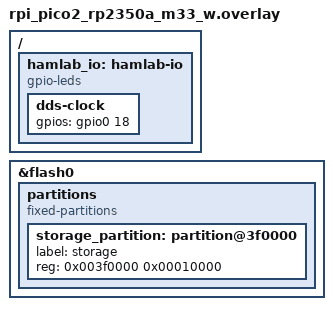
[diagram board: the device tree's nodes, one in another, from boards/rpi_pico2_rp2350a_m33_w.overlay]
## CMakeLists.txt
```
cmake_minimum_required(VERSION 3.20.0)
find_package(Zephyr REQUIRED HINTS $ENV{ZEPHYR_BASE})
project(hamlab)
target_sources(app PRIVATE src/main.c src/network/network.c src/network/tcp_console.c)
```

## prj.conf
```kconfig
CONFIG_GPIO=y
CONFIG_NETWORKING=y
CONFIG_NET_IPV4=y
CONFIG_NET_DHCPV4=y
CONFIG_NET_TCP=y
CONFIG_NET_SOCKETS=y
CONFIG_WIFI=y
CONFIG_NET_MGMT=y
CONFIG_NET_MGMT_EVENT=y
CONFIG_NET_SHELL=y
CONFIG_SHELL=y
CONFIG_SHELL_BACKEND_SERIAL=y
CONFIG_SHELL_BACKEND_TELNET=n
CONFIG_SHELL_BACKEND_DUMMY=y
CONFIG_SHELL_BACKEND_DUMMY_BUF_SIZE=8192
CONFIG_MAIN_STACK_SIZE=4096
CONFIG_SYSTEM_WORKQUEUE_STACK_SIZE=2048
CONFIG_HEAP_MEM_POOL_SIZE=8192
CONFIG_LOG=y
CONFIG_PICOLIBC_IO_FLOAT=y
CONFIG_UDC_DRIVER_LOG_LEVEL_OFF=y
CONFIG_SHELL_STACK_SIZE=5200
CONFIG_NET_TX_STACK_SIZE=2048
CONFIG_NET_RX_STACK_SIZE=2048
CONFIG_NET_PKT_RX_COUNT=16
CONFIG_NET_PKT_TX_COUNT=32
CONFIG_NET_BUF_RX_COUNT=32
CONFIG_NET_BUF_TX_COUNT=64
CONFIG_NET_MAX_CONTEXTS=16
CONFIG_NET_MAX_CONN=16
CONFIG_WIFI_USAGE_MODE_STA=y
CONFIG_NET_L2_WIFI_MGMT=y
CONFIG_NET_L2_WIFI_SHELL=y
CONFIG_NET_CONNECTION_MANAGER=y
CONFIG_NET_MGMT_EVENT_STACK_SIZE=1536
CONFIG_NET_MGMT_EVENT_QUEUE_TIMEOUT=5000
CONFIG_NET_MGMT_EVENT_QUEUE_SIZE=16
CONFIG_WIFI_CREDENTIALS=y
CONFIG_WIFI_CREDENTIALS_BACKEND_SETTINGS=y
CONFIG_SETTINGS=y
CONFIG_FLASH=y
CONFIG_FLASH_MAP=y
CONFIG_NVS=y
CONFIG_SETTINGS_NVS=y
CONFIG_USBD_CDC_ACM_BUF_POOL=y
CONFIG_USBD_CDC_ACM_BUF_POOL_SIZE=4096
```

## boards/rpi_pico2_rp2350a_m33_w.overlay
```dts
/* HamLab uses GPIO directly. See README for the full pin table. */
/ {
    hamlab_io: hamlab-io {
        compatible = "gpio-leds";
        dds-clock { gpios = <&gpio0 18 GPIO_ACTIVE_HIGH>; };
    };
};

/* Identical Settings/NVS storage layout to pico-zephyr-transceiver-control/app.overlay. */
&flash0 {
    partitions {
        compatible = "fixed-partitions";
        #address-cells = <1>;
        #size-cells = <1>;

        storage_partition: partition@3f0000 {
            label = "storage";
            reg = <0x003f0000 0x00010000>;
        };
    };
};
```

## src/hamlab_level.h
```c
#ifndef HAMLAB_LEVEL_H
#define HAMLAB_LEVEL_H
#include <stdint.h>
/* Scope-average reference, 50 ohm sine, 2026-10-01. Offsets include
 * the previous A1 alignment. Endpoints held outside 1..30 MHz. */
static inline double level_offset(int channel,uint32_t hz) {
    const double a[2][3]={{-19.47,-19.39,-18.35},{-19.60,-19.50,-18.46}};
    if(hz<=1000000U)return a[channel][0];
    if(hz>=30000000U)return a[channel][2];
    unsigned i=hz<=7000000U?0:1;
    double lo=i?7000000.0:1000000.0,hi=i?30000000.0:7000000.0;
    return a[channel][i]+(a[channel][i+1]-a[channel][i])*((double)hz-lo)/(hi-lo);
}
#endif
```

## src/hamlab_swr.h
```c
#ifndef HAMLAB_SWR_H
#define HAMLAB_SWR_H
#include <stdint.h>
#include <math.h>
/* Self-built DJ0ABR coupler, closed lid, FY6900; A1 forward, A0 reverse.
 * Open normalization only. Load curve is a quality reference, not vector correction. */
static const struct { uint32_t hz; double open_delta, limit; } swr_cal[] = {
    {1000000U, 0.028000, 26.111000},
    {2000000U, 0.032000, 26.028000},
    {3000000U, 0.054000, 26.091000},
    {4000000U, 0.037000, 26.194000},
    {5000000U, 0.015000, 26.325000},
    {6000000U, 0.039000, 26.449000},
    {7000000U, 0.030000, 26.574000},
    {8000000U, 0.054000, 26.769000},
    {9000000U, 0.027000, 26.909000},
    {10000000U, 0.093000, 27.176000},
    {11000000U, 0.033000, 27.389000},
    {12000000U, 0.004000, 27.570000},
    {13000000U, 0.007000, 27.872000},
    {14000000U, 0.008000, 28.095000},
    {15000000U, 0.009000, 28.377000},
    {16000000U, -0.007000, 28.672000},
    {17000000U, -0.002000, 28.966000},
    {18000000U, 0.011000, 29.306000},
    {19000000U, -0.012000, 29.611000},
    {20000000U, 0.065000, 30.167000},
    {21000000U, -0.024000, 30.178000},
    {22000000U, -0.053000, 30.438000},
    {23000000U, -0.041000, 30.592000},
    {24000000U, -0.045000, 30.827000},
    {25000000U, -0.054000, 30.619000},
    {26000000U, -0.054000, 31.042000},
    {27000000U, -0.051000, 31.227000},
    {28000000U, -0.051000, 31.100000},
    {29000000U, -0.052000, 30.817000},
    {30000000U, -0.080000, 30.706000},
};
static inline int swr_cal_at(uint32_t hz, double *offset, double *limit) {
    unsigned count=sizeof(swr_cal)/sizeof(swr_cal[0]);
    if(hz<swr_cal[0].hz || hz>swr_cal[count-1].hz) return -1;
    for(unsigned i=1;i<count;i++) if(hz<=swr_cal[i].hz) {
        double t=(double)(hz-swr_cal[i-1].hz)/(swr_cal[i].hz-swr_cal[i-1].hz);
        *offset=swr_cal[i-1].open_delta+t*(swr_cal[i].open_delta-swr_cal[i-1].open_delta);
        *limit=swr_cal[i-1].limit+t*(swr_cal[i].limit-swr_cal[i-1].limit);
        return 0;
    }
    return -1;
}
#endif
```

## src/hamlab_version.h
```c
#ifndef HAMLAB_VERSION_H_
#define HAMLAB_VERSION_H_

#define HAMLAB_VERSION "0.3.7"

#endif
```

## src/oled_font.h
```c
/* 6x8 monochrome glyphs, ASCII 32..126, generated from DejaVu Sans Mono. */
#ifndef HAMLAB_OLED_FONT_H_
#define HAMLAB_OLED_FONT_H_
static const uint8_t oled_font[95][6] = {
    {0x00, 0x00, 0x00, 0x00, 0x00, 0x00},
    {0x00, 0x00, 0x5f, 0x00, 0x00, 0x00},
    {0x00, 0x03, 0x00, 0x03, 0x00, 0x00},
    {0x54, 0x3e, 0x75, 0x1f, 0x14, 0x00},
    {0x00, 0x4c, 0x4a, 0xff, 0x52, 0x32},
    {0x07, 0x15, 0x7f, 0x58, 0x74, 0x00},
    {0x00, 0x30, 0x4f, 0x79, 0x51, 0x00},
    {0x00, 0x00, 0x03, 0x00, 0x00, 0x00},
    {0x00, 0x00, 0x3f, 0x40, 0x00, 0x00},
    {0x00, 0x00, 0x61, 0x1e, 0x00, 0x00},
    {0x09, 0x06, 0x0f, 0x06, 0x09, 0x00},
    {0x10, 0x10, 0x7c, 0x10, 0x10, 0x00},
    {0x00, 0x00, 0xc0, 0x00, 0x00, 0x00},
    {0x00, 0x00, 0x10, 0x10, 0x00, 0x00},
    {0x00, 0x00, 0x40, 0x00, 0x00, 0x00},
    {0x40, 0x38, 0x0e, 0x01, 0x00, 0x00},
    {0x00, 0x3e, 0x41, 0x49, 0x3e, 0x00},
    {0x00, 0x00, 0x41, 0x7f, 0x40, 0x00},
    {0x00, 0x62, 0x71, 0x59, 0x4e, 0x00},
    {0x00, 0x42, 0x49, 0x49, 0x36, 0x00},
    {0x00, 0x30, 0x2c, 0x7f, 0x20, 0x00},
    {0x00, 0x4f, 0x49, 0x49, 0x31, 0x00},
    {0x00, 0x3e, 0x4b, 0x49, 0x39, 0x00},
    {0x00, 0x01, 0x61, 0x3d, 0x03, 0x00},
    {0x00, 0x36, 0x49, 0x49, 0x36, 0x00},
    {0x00, 0x4e, 0x49, 0x69, 0x3e, 0x00},
    {0x00, 0x00, 0x44, 0x00, 0x00, 0x00},
    {0x00, 0x00, 0xc4, 0x00, 0x00, 0x00},
    {0x00, 0x10, 0x18, 0x18, 0x28, 0x24},
    {0x28, 0x28, 0x28, 0x28, 0x28, 0x00},
    {0x00, 0x24, 0x28, 0x18, 0x18, 0x10},
    {0x00, 0x01, 0x59, 0x05, 0x03, 0x00},
    {0x00, 0x7c, 0xc2, 0xba, 0x3c, 0x00},
    {0x00, 0x78, 0x27, 0x27, 0x78, 0x00},
    {0x00, 0x7f, 0x49, 0x49, 0x76, 0x00},
    {0x00, 0x3e, 0x41, 0x41, 0x41, 0x00},
    {0x00, 0x7f, 0x41, 0x41, 0x3e, 0x00},
    {0x00, 0x7f, 0x49, 0x49, 0x49, 0x00},
    {0x00, 0x7f, 0x09, 0x09, 0x09, 0x00},
    {0x00, 0x3e, 0x41, 0x49, 0x79, 0x00},
    {0x00, 0x7f, 0x08, 0x08, 0x7f, 0x00},
    {0x00, 0x41, 0x7f, 0x41, 0x00, 0x00},
    {0x00, 0x40, 0x41, 0x41, 0x7f, 0x00},
    {0x00, 0x7f, 0x0c, 0x32, 0x41, 0x00},
    {0x00, 0x7f, 0x40, 0x40, 0x40, 0x00},
    {0x00, 0x7f, 0x1e, 0x1e, 0x7f, 0x00},
    {0x00, 0x7f, 0x06, 0x38, 0x7f, 0x00},
    {0x00, 0x3e, 0x41, 0x41, 0x3e, 0x00},
    {0x00, 0x7f, 0x09, 0x09, 0x06, 0x00},
    {0x00, 0x3e, 0x41, 0x41, 0xbe, 0x00},
    {0x00, 0x7f, 0x09, 0x19, 0x36, 0x40},
    {0x00, 0x26, 0x49, 0x49, 0x3a, 0x00},
    {0x01, 0x01, 0x7f, 0x01, 0x01, 0x00},
    {0x00, 0x3f, 0x40, 0x40, 0x3f, 0x00},
    {0x00, 0x03, 0x7c, 0x7c, 0x03, 0x00},
    {0x0f, 0x78, 0x04, 0x78, 0x0f, 0x00},
    {0x00, 0x63, 0x1c, 0x1c, 0x63, 0x00},
    {0x01, 0x06, 0x78, 0x06, 0x01, 0x00},
    {0x00, 0x61, 0x51, 0x4d, 0x43, 0x00},
    {0x00, 0x00, 0x7f, 0x40, 0x00, 0x00},
    {0x01, 0x0e, 0x38, 0x40, 0x00, 0x00},
    {0x00, 0x00, 0x40, 0x7f, 0x00, 0x00},
    {0x02, 0x02, 0x01, 0x02, 0x00, 0x00},
    {0x00, 0x00, 0x00, 0x00, 0x00, 0x00},
    {0x00, 0x00, 0x01, 0x00, 0x00, 0x00},
    {0x00, 0x74, 0x54, 0x54, 0x78, 0x00},
    {0x00, 0x7f, 0x44, 0x44, 0x38, 0x00},
    {0x00, 0x38, 0x44, 0x44, 0x44, 0x00},
    {0x00, 0x38, 0x44, 0x44, 0x7f, 0x00},
    {0x00, 0x38, 0x54, 0x54, 0x58, 0x00},
    {0x00, 0x04, 0x7f, 0x04, 0x04, 0x00},
    {0x00, 0x38, 0x44, 0x44, 0xfc, 0x00},
    {0x00, 0x7f, 0x04, 0x04, 0x7c, 0x00},
    {0x40, 0x44, 0x7c, 0x40, 0x40, 0x00},
    {0x00, 0x00, 0x04, 0xfc, 0x00, 0x00},
    {0x00, 0x7f, 0x10, 0x28, 0x44, 0x00},
    {0x00, 0x00, 0x3f, 0x40, 0x40, 0x00},
    {0x00, 0x7c, 0x04, 0x7c, 0x04, 0x7c},
    {0x00, 0x7c, 0x04, 0x04, 0x7c, 0x00},
    {0x00, 0x38, 0x44, 0x44, 0x38, 0x00},
    {0x00, 0xfc, 0x44, 0x44, 0x38, 0x00},
    {0x00, 0x38, 0x44, 0x44, 0xfc, 0x00},
    {0x00, 0x00, 0x7c, 0x04, 0x04, 0x00},
    {0x00, 0x4c, 0x54, 0x54, 0x74, 0x00},
    {0x00, 0x04, 0x7e, 0x44, 0x44, 0x00},
    {0x00, 0x7c, 0x40, 0x40, 0x7c, 0x00},
    {0x00, 0x0c, 0x70, 0x70, 0x0c, 0x00},
    {0x0c, 0x70, 0x08, 0x70, 0x0c, 0x00},
    {0x00, 0x44, 0x38, 0x38, 0x44, 0x00},
    {0x00, 0x0c, 0xf0, 0x30, 0x0c, 0x00},
    {0x00, 0x44, 0x74, 0x5c, 0x44, 0x00},
    {0x00, 0x04, 0x7b, 0x40, 0x00, 0x00},
    {0x00, 0x00, 0xff, 0x00, 0x00, 0x00},
    {0x00, 0x40, 0x7b, 0x04, 0x00, 0x00},
    {0x00, 0x08, 0x08, 0x08, 0x10, 0x10},
};
#endif
```
